# RT58X register map
Series: ARMv8-M Mainline; File version: 1.0
CPU: CM3 r0p0, little endian, MPU, no FPU, VTOR, 3 interrupt priority bits
Registers are 32-bit, read-write, reset 0x0 unless marked. A register's access mark holds for its fields unless they carry their own. Offsets are from the block's base; [hi:lo] are bit positions.

## XDMA — XDMA Register block
Base 0xA0B00000
0x00 CTL0_REG reset 0x1 — ctl0
  [0] cfg_xdma_en — Enable XDMA 0: disable 1: enable
    0=B_0 (Enable XDMA 0: disable 1: enable)
0x04 CTL1_REG wo — ctl1
  [0] cfg_xdma_rst — Reset XDMA 0: disable 1: reset
    0=B_0 (Reset XDMA 0: disable 1: reset)

## CRYPTO — CRYPTO Register block
Base 0xA0E00000
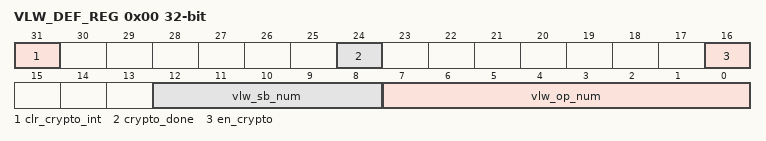
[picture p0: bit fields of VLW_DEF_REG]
0x00 VLW_DEF_REG — vlw def
  [31] clr_crypto_int wo
    0=B_31 (clr crypto int)
  [24] crypto_done ro
    0=B_24 (crypto done)
  [16] en_crypto wo — 1: enable crypto cell
    0=B_16 (1: enable crypto cell)
  [12:8] vlw_sb_num — Sign bit position at most significant word.
    0=B_8_to_12 (Sign bit position at most significant word.)
  [7:0] vlw_op_num — number - 1 of long word(32bit for ECC) Exp: p256 --> (256/32) = 8, p521 --> (521/32) = 16.28125 -->16
    0=B_0_to_7 (number - 1 of long word(32bit for ECC) Exp: p256 --> (256/32) = 8, p521 --> (521/32) = 16.28125 -->16)

## TIMER2 — TIMER2 Register block
Base 0xA0F00000
0x00 T2_LOAD_REG — The initial value of the timer. Also, the reload value when the timer is in periodic mode.
0x04 T2_VALUE_REG ro — The current value of the timer synchronized to the PCLK domain. Note that in cases where PCLK is slow, this value may significantly differ from the actual internal count.
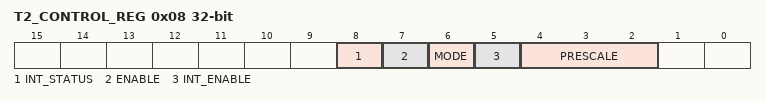
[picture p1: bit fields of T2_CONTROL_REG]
0x08 T2_CONTROL_REG — t2 control
  [8] INT_STATUS ro — Interrupt Status. 0: Timer interrupt is inactive 1: Timer interrupt active.
    0=B_8 (Interrupt Status. 0: Timer interrupt is inactive 1: Timer interrupt active.)
  [7] ENABLE — 0: Timer Disabled 1: Timer Enabled
    0=B_7 (0: Timer Disabled 1: Timer Enabled)
  [6] MODE — 0: Free running mode 1: Periodic mode.
    0=B_6 (0: Free running mode 1: Periodic mode.)
  [5] INT_ENABLE — 0: Timer interrupt disable 1: Timer interrupt enable.
    0=B_5 (0: Timer interrupt disable 1: Timer interrupt enable.)
  [4:2] PRESCALE — 0: clock is divided by one 1: clock is divided by 16 2: clock is divided by 256 3: clock is divided by 2 4: clock is divided by 8 5: clock is divided by 32 6: clock is divided by 128 7: clock is divided by 1024
    0=B_2_to_4 (0: clock is divided by one 1: clock is divided by 16 2: clock is divided by 256 3: clock is divided by 2 4: clock is divided by 8 5: clock is divided by 32 6: clock is divided by 128 7: clock is divided by 1024)
0x0C T2_CLEAR_REG — Clear Interrupt – write any value to clear the timer interrupt.

## TIMER3 — TIMER3 Register block
Base 0xA0F40000
0x00 T3_LOAD_REG — The initial value of the timer. Also, the reload value when the timer is in periodic mode.
0x04 T3_VALUE_REG ro — The current value of the timer synchronized to the PCLK domain. Note that in cases where PCLK is slow, this value may significantly differ from the actual internal count.
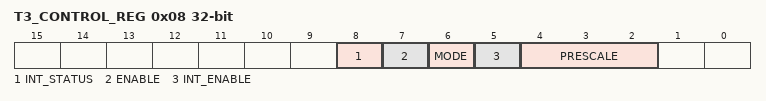
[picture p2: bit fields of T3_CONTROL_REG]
0x08 T3_CONTROL_REG — t3 control
  [8] INT_STATUS ro — Interrupt Status. 0: Timer interrupt is inactive 1: Timer interrupt active.
    0=B_8 (Interrupt Status. 0: Timer interrupt is inactive 1: Timer interrupt active.)
  [7] ENABLE — 0: Timer Disabled 1: Timer Enabled
    0=B_7 (0: Timer Disabled 1: Timer Enabled)
  [6] MODE — 0: Free running mode 1: Periodic mode.
    0=B_6 (0: Free running mode 1: Periodic mode.)
  [5] INT_ENABLE — 0: Timer interrupt disable 1: Timer interrupt enable.
    0=B_5 (0: Timer interrupt disable 1: Timer interrupt enable.)
  [4:2] PRESCALE — 0: clock is divided by one 1: clock is divided by 16 2: clock is divided by 256 3: clock is divided by 2 4: clock is divided by 8 5: clock is divided by 32 6: clock is divided by 128 7: clock is divided by 1024
    0=B_2_to_4 (0: clock is divided by one 1: clock is divided by 16 2: clock is divided by 256 3: clock is divided by 2 4: clock is divided by 8 5: clock is divided by 32 6: clock is divided by 128 7: clock is divided by 1024)
0x0C T3_CLEAR_REG — Clear Interrupt – write any value to clear the timer interrupt.
0x10 T3_REPEAT_DELAY_REG — t3 repeat delay
  [15:0] INT_REPEAT_DELAY — Interrupt is active after times. It is only valid when sleep mode is enabled. 16'd0=interrupt is active at the 1st event occurs 16'd1=interrupt is active at the 2nd event occurs …

## TIMER4 — TIMER4 Register block
Base 0xA0F80000
0x00 T4_LOAD_REG — The initial value of the timer. Also, the reload value when the timer is in periodic mode.
0x04 T4_VALUE_REG ro — The current value of the timer synchronized to the PCLK domain. Note that in cases where PCLK is slow, this value may significantly differ from the actual internal count.
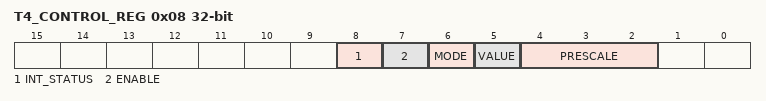
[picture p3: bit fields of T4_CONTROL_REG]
0x08 T4_CONTROL_REG — t4 control
  [8] INT_STATUS ro — Interrupt Status. 0: Timer interrupt is inactive 1: Timer interrupt active.
    0=B_8 (Interrupt Status. 0: Timer interrupt is inactive 1: Timer interrupt active.)
  [7] ENABLE — 0: Timer Disabled 1: Timer Enabled
    0=B_7 (0: Timer Disabled 1: Timer Enabled)
  [6] MODE — 0: Free running mode 1: Periodic mode.
    0=B_6 (0: Free running mode 1: Periodic mode.)
  [5] VALUE — 0: Timer interrupt disable 1: Timer interrupt enable.
    0=B_5 (0: Timer interrupt disable 1: Timer interrupt enable.)
  [4:2] PRESCALE — 0: clock is divided by one 1: clock is divided by 16 2: clock is divided by 256 3: clock is divided by 2 4: clock is divided by 8 5: clock is divided by 32 6: clock is divided by 128 7: clock is divided by 1024
    0=B_2_to_4 (0: clock is divided by one 1: clock is divided by 16 2: clock is divided by 256 3: clock is divided by 2 4: clock is divided by 8 5: clock is divided by 32 6: clock is divided by 128 7: clock is divided by 1024)
0x0C T4_CLEAR_REG — Clear Interrupt – write any value to clear the timer interrupt.
0x10 T4_REPEAT_DELAY_REG — t4 repeat delay
  [15:0] INT_REPEAT_DELAY — Interrupt is active after times. It is only valid when sleep mode is enabled. 16'd0=interrupt is active at the 1st event occurs 16'd1=interrupt is active at the 2nd event occurs …
